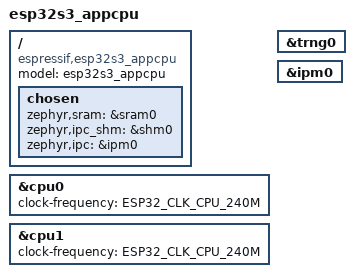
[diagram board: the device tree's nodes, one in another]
/*
 * Copyright (c) 2023 Espressif Systems (Shanghai) Co., Ltd.
 *
 * SPDX-License-Identifier: Apache-2.0
 */
/dts-v1/;

#include <espressif/esp32s3/esp32s3_appcpu.dtsi>
/ {
	model = "esp32s3_appcpu";
	compatible = "espressif,esp32s3_appcpu";

	chosen {
		zephyr,sram = &sram0;
		zephyr,ipc_shm = &shm0;
		zephyr,ipc = &ipm0;
	};
};

&cpu0 {
	clock-frequency = <ESP32_CLK_CPU_240M>;
};

&cpu1 {
	clock-frequency = <ESP32_CLK_CPU_240M>;
};

&trng0 {
	status = "okay";
};

&ipm0 {
	status = "okay";
};
